# IND83212 register map
Series: Verne; File version: B0
CPU: CM0 r0p1, selectable endian, no MPU, no FPU, 4 interrupt priority bits
Registers are 32-bit, read-write, no defined reset value unless marked. A register's access mark holds for its fields unless they carry their own. Offsets are from the block's base; [hi:lo] are bit positions.

## PMUA — Power Management Unit
Base 0x50000040; register names take the prefix PMUA_
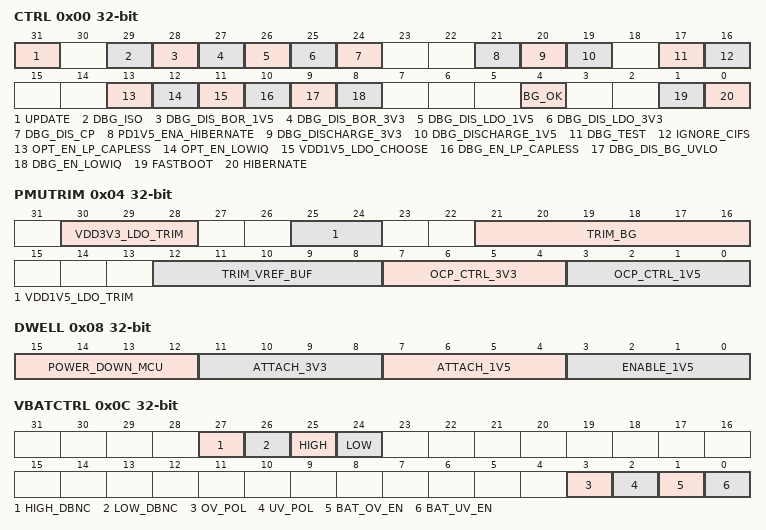
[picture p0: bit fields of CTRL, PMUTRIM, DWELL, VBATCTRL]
0x00 CTRL — Control
  [31] UPDATE dual — PMUA Configure Update. Set to update the Configurations to PRE5V domains. NOTE: DO NOT change the CTRL register when it is high, which indicates there is an update in progress, It gets cleared by the core when the current update is done
  [29] DBG_ISO — NOTE:Don't use. Debug Contrl of isolation of domain 1V5 to domain PRE5V at PMU debug mode. NOTE: The write operation of this register takes effect by PMU_SFRS->CTRL.UPDATE at PMU debug mode
  [28] DBG_DIS_BOR_1V5 — Debug Contrl of dis_bor_1v5 at PMU debug mode. NOTE: The write operation of this register takes effect by PMU_SFRS->CTRL.UPDATE at PMU debug mode
  [27] DBG_DIS_BOR_3V3 — Debug Contrl of dis_bor_3v3 at PMU debug mode. NOTE: The write operation of this register takes effect by PMU_SFRS->CTRL.UPDATE at PMU debug mode
  [26] DBG_DIS_LDO_1V5 — Debug Contrl of dis_ldo_1v5 at PMU debug mode.(Not Use) NOTE: The write operation of this register takes effect by PMU_SFRS->CTRL.UPDATE at PMU debug mode
  [25] DBG_DIS_LDO_3V3 — NOTE:Don't use.Debug Contrl of dis_ldo_3v3 at PMU debug mode. NOTE: The write operation of this register takes effect by PMU_SFRS->CTRL.UPDATE at PMU debug mode
  [24] DBG_DIS_CP — Set 1, Shut down PRE5V ChargePump, PRE5V=Vzener-Vgs. Only take effect at Debug mode(DBG_TEST = 1) at PMU debug mode
  [21] PD1V5_ENA_HIBERNATE — enable of 1V5 Power Domain at Hibernate mode. set to enable the 1V5 Power Domain at Hibernate mode, this mode is defined as DEEPSLEEP mode. NOTE: The write operation of this register takes effect by PMU_SFRS->CTRL.UPDATE at PMU debug mode
  [20] DBG_DISCHARGE_3V3 — 3V3 LDO Debug Mode: a. Set '0' to test 3V3-LDO function; b. Set '1' to test 3V3-LDO Discharge Circuit. NOTE: The write operation of this register takes effect by PMU_SFRS->CTRL.UPDATE at PMU debug mode
  [19] DBG_DISCHARGE_1V5 — 1V5 LDO Debug Mode: a. Set '0' to test 1V5-LDO function; b. Set '1' to test 1V5-LDO Discharge Circuit. NOTE: The write operation of this register takes effect by PMU_SFRS->CTRL.UPDATE at PMU debug mode
  [17] DBG_TEST — PRE5V DBG mode enable. Set 1, Pre5V voltage can output through 3P3V LDO pin(DBG_DIS_LDO_3V3 = 1'b0 for enable 3v3-LDO).
  [16] IGNORE_CIFS — Ignore QACKs. Setting a bit in this register prevents PMUA from waiting for the assertion of the corresponding 'Quiescent State Acknowlege' signal when before transitioning towards the Hibernate state.
  [13] OPT_EN_LP_CAPLESS — 1.5V ldo low power mode, set 1 to enter low power at Deepsleep mode. NOTE: The write operation of this register takes effect by PMU_SFRS->CTRL.UPDATE at Trim mode
  [12] OPT_EN_LOWIQ — Set to enable of low power mode for BG_TOP at Deepsleep Mode. NOTE: The write operation of this register takes effect by PMU_SFRS->CTRL.UPDATE at Trim mode
  [11] VDD1V5_LDO_CHOOSE — 1.5V LDO Mode selection. NOTE: This register is not used by Analog PMU 0x0: choose Capless LDO 0x1: choose Caps LDO
  [10] DBG_EN_LP_CAPLESS — 1.5V ldo low power mode, set 1 to enter low power at PMU debug mode. NOTE: The write operation of this register takes effect by PMU_SFRS->CTRL.UPDATE at PMU debug mode
  [9] DBG_DIS_BG_UVLO — Set to disable of low power mode for UVLO in BG_TOP at PMU debug mode. NOTE: The write operation of this register takes effect by PMU_SFRS->CTRL.UPDATE at PMU debug mode
  [8] DBG_EN_LOWIQ — Set to enable of low power mode for BG_TOP at PMU debug mode. NOTE: The write operation of this register takes effect by PMU_SFRS->CTRL.UPDATE at PMU debug mode
  [4] BG_OK ro — the flag of bandgap OK. the flag of bandgap OK
  [1] FASTBOOT — Fast boot. Set to enable used of the fast clock during subsequent power-up sequences (including the portion consumed by the Clough boot sequence). The set value brings the system up with the slow clock to make the initial boot and any boot after a hard reset (e.g. after a brownout) as safe as possible.
  [0] HIBERNATE wo — Hibernate. Set to put the chip into HIBERATE mode. Before setting this bit, ensure that wake interrupt controller HOLD bit has been set (and that a corresponding Lullaby interrupt has been received).
0x04 PMUTRIM
  [30:28] VDD3V3_LDO_TRIM — 3.3V LDO output trim.The write operation of this register takes effect by PMU_SFRS->CTRL.UPDATE at PMU debug mode 0x0: 3.40V 0x1: 3.00V 0x2: 3.09V 0x3: 3.18V 0x4: 3.28V 0x5: 3.52V 0x6: 3.65V 0x7: 3.80V
  [25:24] VDD1V5_LDO_TRIM — 1.5V LDO output trim. The write operation of this register takes effect by PMU_SFRS->CTRL.UPDATE at PMU debug mode 0x0: 1.55V 0x1: 1.61V 0x2: 1.65V 0x3: 1.69V
  [21:16] TRIM_BG — Trim BandGap. (1) The voltage range before trimming is 1.16797V ~ 1.26337V. (2) The trim ratio 1/1.4811. (3) The voltage is 1.21455V while TRIM_BG == 0x0. The write operation of this register takes effect by PMU_SFRS->CTRL.UPDATE at PMU debug mode
  [12:8] TRIM_VREF_BUF — Trim the buffer refernce voltage include VREF_1/VREF_1P1/VREF_0P75/VREF_0P6. (1) The voltage range before trimming is 1.19825V ~ 1.237V. (2) The step is 1.25mV, and the precision of trimming is +- 0.625mV. (3) The voltage is 1.217V while TRIM_VREF_BUF == 0x0. The write operation of this register takes effect by PMU_SFRS->CTRL.UPDATE at PMU debug mode
  [7:4] OCP_CTRL_3V3 — OCP trim for 3P3V LDO(default 30mA) .The write operation of this register takes effect by PMU_SFRS->CTRL.UPDATE at PMU debug mode. 0x0: 10.0 mA 0x1: 12.5 mA 0x2: 15.0 mA 0x3: 17.5 mA 0x4: 20.0 mA 0x5: 22.5 mA 0x6: 25.0 mA 0x7: 27.5 mA 0x8: 30.0 mA 0x9: 32.5 mA 0xa: 35.0 mA 0xb: 37.5 mA 0xc: 40.0 mA 0xd: 42.5 mA 0xe: 45.0 mA 0xf: 47.5 mA
  [3:0] OCP_CTRL_1V5 — OCP trim for 1.5V LDO(default 30mA) .The write operation of this register takes effect by PMU_SFRS->CTRL.UPDATE at PMU debug mode. 0x0: 20.0 mA 0x1: 22.5 mA 0x2: 25.0 mA 0x3: 27.5 mA 0x4: 30.0 mA 0x5: 32.5 mA 0x6: 35.0 mA 0x7: 37.5 mA 0x8: 40.0 mA 0x9: 42.5 mA 0xa: 45.0 mA 0xb: 47.5 mA 0xc: 50.0 mA 0xd: 52.5 mA 0xe: 55.0 mA 0xf: 57.5 mA
0x08 DWELL
  [15:12] POWER_DOWN_MCU — Power down MCU dwell time. Defines the amount of time spent in the 'Power down MCU' state. Pausing here allows the MCU supplies to discharge (to guarantee subsequent POR).at PMU debug mode
  [11:8] ATTACH_3V3 — Attach 3.3V dwell time. Defines the amount of time spent in the 'Attach 3V3' state. State Attaches 3.3V to MCU.at PMU debug mode
  [7:4] ATTACH_1V5 — Attach 1.5V dwell time. Defines the amount of time spent in the 'Attach 1V5' state. State Attaches 1.5V to MCU.at PMU debug mode
  [3:0] ENABLE_1V5 — Enable 1.5V dwell time. Defines the amount of time spent in the 'Enable 1V5' state. Allows 3v3 and 1v5 regs to settle.at PMU debug mode
0x0C VBATCTRL — VBAT Monitor Register
  [27] HIGH_DBNC ro — Battery Voltage High Status after deboucing. Battery monitor over voltage event signal coming from the debouncer of analog comparator circuit.
  [26] LOW_DBNC ro — Battery Voltage Low Status after debouncing. Battery monitor under voltage event signal coming from the debouncer of analog comparator circuit.
  [25] HIGH ro — Battery Voltage High Status. RAW battery monitor over voltage event signal coming from the analog comparator circuit.
  [24] LOW ro — Battery Voltage Low Status. RAW battery monitor under voltage event signal coming from the analog comparator circuit.
  [3] OV_POL — Battery Voltage Monitor Over Voltage Interrupt Event Polarity. Flips the over voltage event signal coming from the analog comparator circuit which feeds into the interrupt generator. 0x0: Native Polarity 0x1: Flip Polarity
  [2] UV_POL — Battery Voltage Monitor Under Voltage Interrupt Event Polarity. Flips the under voltage event signal coming from the analog comparator circuit which feeds into the interrupt generator. 0x0: Native Polarity 0x1: Flip Polarity
  [1] BAT_OV_EN — Battery Over Voltage Monitor Enable. Set to enable the vbat over voltage monitor analog comparator circuit.The write operation of this register takes effect by PMU_SFRS->CTRL.UPDATE
  [0] BAT_UV_EN — Battery Under Voltage Monitor Enable. Set to enable the vbat under voltage monitor analog comparator circuit.The write operation of this register takes effect by PMU_SFRS->CTRL.UPDATE
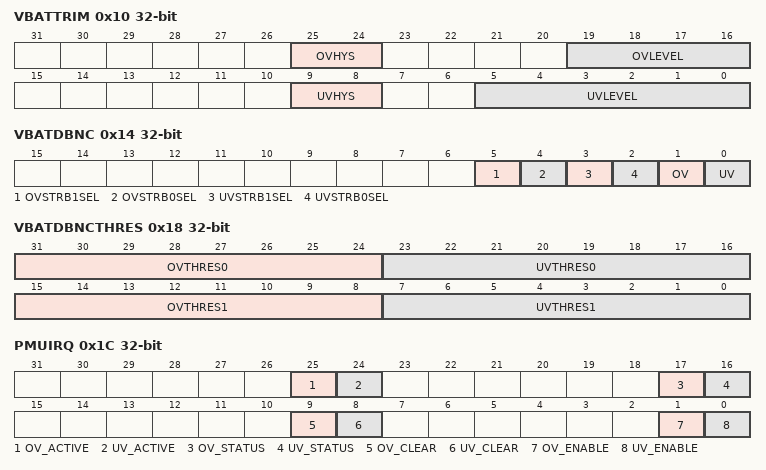
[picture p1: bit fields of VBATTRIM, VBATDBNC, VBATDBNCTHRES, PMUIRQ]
0x10 VBATTRIM — VBAT Monitor Trim Register
  [25:24] OVHYS — Battery Voltage Monitor Over Voltage Hysterisis Select. Selects the hysterisis level for the Over Voltage monitor.The write operation of this register takes effect by PMU_SFRS->CTRL.UPDATE 0x0: 0.359V 0x1: 0.720V 0x2: 1.080V 0x3: 1.440V
  [19:16] OVLEVEL — Battery Voltage Monitor Over Voltage Select. Selects the reference level for the Over Voltage monitor to output one-hot Configuration to Analog Module.(If OVLEVEL>9, the actual analog trim value is the same as default value:OVLEVEL=0x07).The write operation of this register takes effect by PMU_SFRS->CTRL.UPDATE 0x0: Over Voltage Threshold- 10'h001: 14.75V 0x1: Over Voltage Threshold- 10'h002: 15.18V 0x2: Over Voltage Threshold- 10'h004: 15.65V 0x3: Over Voltage Threshold- 10'h008: 16.37V 0x4: Over Voltage Threshold- 10'h010: 16.85V 0x5: Over Voltage Threshold- 10'h020: 17.57V 0x6: Over Voltage Threshold- 10'h040: 18.30V 0x7: Over Voltage Threshold- 10'h080: 19.00V 0x8: Over Voltage Threshold- 10'h100: 19.97V 0x9: Over Voltage Threshold- 10'h200: 20.70V
  [9:8] UVHYS — Battery Voltage Monitor Under Voltage Hysterisis Select. Selects the hysterisis level for the Under Voltage monitor.The write operation of this register takes effect by PMU_SFRS->CTRL.UPDATE 0x0: 0.475V 0x1: 0.835V 0x2: 1.225V 0x3: 1.635V
  [5:0] UVLEVEL — Battery Voltage Monitor Under Voltage Select. Selects the reference level for the Under Voltage monitor. If UVLEVEL[5:3]>0x04, the actual analog trim value is the same as UVLEVEL=0x0A. The UVLEVEL threshold is mononically increased with the setting.The write operation of this register takes effect by PMU_SFRS->CTRL.UPDATE 0x0: Vf: 4.615V 0x1: Vf: 4.685V 0x7: Vf: 5.135V 0x8: Vf: 5.225V 0x9: Vf: 5.135V 0xa: Vf: 5.405V 0xf: Vf: 5.895V 0x10: Vf: 6.015V 0x11: Vf: 6.125V 0x17: Vf: 6.925V 0x18: Vf: 7.075V 0x19: Vf: 7.235V 0x1f: Vf: 8.385V 0x20: Vf: 8.605V 0x21: Vf: 8.845V 0x27: Vf:10.610V
0x14 VBATDBNC — VBAT Debounce Register
  [5] OVSTRB1SEL — Low frequency strobing select for debouncing. Enables strobing 1 with the Low frequency clock(16K) instead of just clocking with High frequency Clock(16M). Default is set to 0 for quick acknowledgement of OV event.
  [4] OVSTRB0SEL — Low frequency strobing select for debouncing. Enables strobing 0 with the Low frequency clock(16K) instead of just clocking with High frequency Clock(16M). Default is set to 1 for debouncing of OV.
  [3] UVSTRB1SEL — Low frequency strobing select for debouncing. Enables strobing 1 with the Low frequency clock(16K) instead of just clocking with High frequency Clock(16M). Default is set to 0 for quick acknowledgement of UV event.
  [2] UVSTRB0SEL — Low frequency strobing select for debouncing. Enables strobing 0 with the Low frequency clock(16K) instead of just clocking with High frequency Clock(16M). Default is set to 1 for debouncing of UV.
  [1] OV — over voltage signal debounce enable. if set to '1, debounces the over voltage signal before going to over voltage interrupt generation else the signal bypass the debouncer
  [0] UV — under voltage signal debounce enable. if set to '1, debounces the under voltage signal before going to under voltage interrupt generation else the signal bypass the debouncer
0x18 VBATDBNCTHRES — VBAT Monitor Threshold Register
  [31:24] OVTHRES0 — Over Voltage debouncing threshold for 1to0 Transition. Sets the threshold for debouncing the over voltage event going from 1 to 0. It will require the ov event to stay high for the (OVTHRES0+1) number of LF/HF clocks to transit from a 1 to 0.
  [23:16] UVTHRES0 — Under Voltage debouncing threshold for 1to0 Transition. Sets the threshold for debouncing the under voltage event going from 1 to 0. It will require the uv event to stay high for the (UVTHRES0+1) number of LF/HF clocks to transit from a 1 to 0.
  [15:8] OVTHRES1 — Over Voltage debouncing threshold for 0to1 Transition. Sets the threshold for debouncing the over voltage event going from 0 to 1. It will require the ov event to stay high for the (OVTHRES1+1) number of LF/HF clocks to transit from a 0 to 1.
  [7:0] UVTHRES1 — Under Voltage debouncing threshold for 0to1 Transition. Sets the threshold for debouncing the under voltage event going from 0 to 1. It will require the uv event to stay high for the (UVTHRES1+1) number of LF/HF clocks to transit from a 0 to 1.
0x1C PMUIRQ — Voltage Monitor interrupts
  [25] OV_ACTIVE ro — over voltage interrupt active.
  [24] UV_ACTIVE ro — under voltage interrupt active.
  [17] OV_STATUS ro — over voltage interrupt status.
  [16] UV_STATUS ro — under voltage interrupt status.
  [9] OV_CLEAR wo — over voltage interrupt clear. Autoclear: includes a synchronous reset signal which clears the register on the cycle following write.
  [8] UV_CLEAR wo — under voltage interrupt clear. Autoclear: includes a synchronous reset signal which clears the register on the cycle following write.
  [1] OV_ENABLE — over voltage interrupt enable.
  [0] UV_ENABLE — under voltage interrupt enable.
